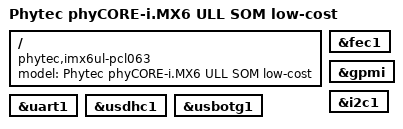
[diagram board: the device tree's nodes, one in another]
// SPDX-License-Identifier: (GPL-2.0-or-later OR MIT)
/*
 * Copyright (C) 2018 PHYTEC Messtechnik GmbH
 * Author: Stefan Riedmueller <s.riedmueller@phytec.de>
 */

/dts-v1/;

#include <arm/imx6ull.dtsi>
#include "imx6ul-phytec-phycore-som.dtsi"

/ {
	model = "Phytec phyCORE-i.MX6 ULL SOM low-cost";
	compatible = "phytec,imx6ul-pcl063", "fsl,imx6ull";
};

&fec1 {
	status = "okay";
};

&gpmi {
	status = "okay";
};

&i2c1 {
	status = "okay";
};

&uart1 {
	status = "okay";
};

&usdhc1 {
	status = "okay";
};

&usbotg1 {
	status = "okay";
};
